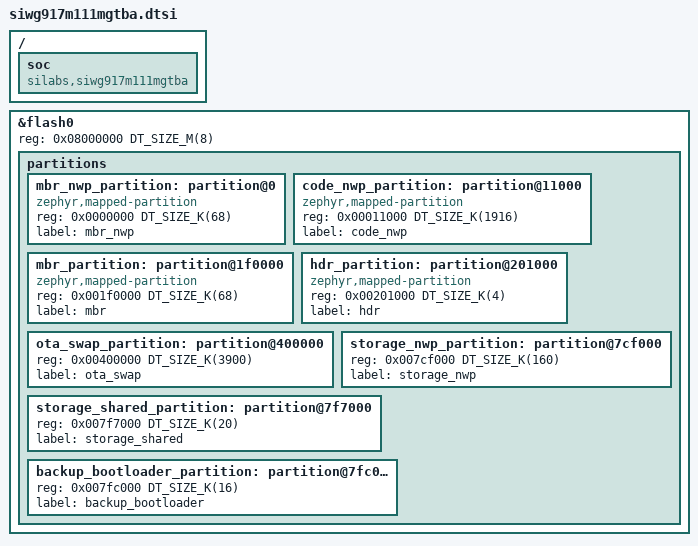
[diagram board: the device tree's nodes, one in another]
/*
 * Copyright (c) 2023 Antmicro
 * Copyright (c) 2024 Silicon Laboratories Inc.
 *
 * SPDX-License-Identifier: Apache-2.0
 */

#include <mem.h>
#include <silabs/siwg917.dtsi>

/ {
	soc {
		compatible = "silabs,siwg917m111mgtba", "silabs,siwg917",
			     "silabs,siwx91x", "simple-bus";
	};
};

&flash0 {
	reg = <0x08000000 DT_SIZE_M(8)>;
	ranges = <0 0x08000000 DT_SIZE_M(8)>;

	partitions {
		ranges;
		#address-cells = <1>;
		#size-cells = <1>;

		/* See AN1416: SiWx917 SoC Memory Map, 3.1.4 Memory Map (8 MB) */
		mbr_nwp_partition: partition@0 {
			compatible = "zephyr,mapped-partition";
			reg = <0x0000000 DT_SIZE_K(68)>;
			label = "mbr_nwp";
		};

		code_nwp_partition: partition@11000 {
			compatible = "zephyr,mapped-partition";
			reg = <0x00011000 DT_SIZE_K(1916)>;
			label = "code_nwp";
		};

		mbr_partition: partition@1f0000 {
			compatible = "zephyr,mapped-partition";
			reg = <0x001f0000 DT_SIZE_K(68)>;
			label = "mbr";
		};

		hdr_partition: partition@201000 {
			compatible = "zephyr,mapped-partition";
			reg = <0x00201000 DT_SIZE_K(4)>;
			label = "hdr";
		};

		/* 0x00202000-0x00400000: Free space for Zephyr */

		ota_swap_partition: partition@400000 {
			reg = <0x00400000 DT_SIZE_K(3900)>;
			/* During the upgrade process, this area will be copied to
			 * 0x011000-0x400000
			 */
			label = "ota_swap";
		};

		storage_nwp_partition: partition@7cf000 {
			reg = <0x007cf000 DT_SIZE_K(160)>;
			label = "storage_nwp";
		};

		storage_shared_partition: partition@7f7000 {
			reg = <0x007f7000 DT_SIZE_K(20)>;
			label = "storage_shared";
		};

		backup_bootloader_partition: partition@7fc000 {
			reg = <0x007fc000 DT_SIZE_K(16)>;
			label = "backup_bootloader";
		};
	};
};
